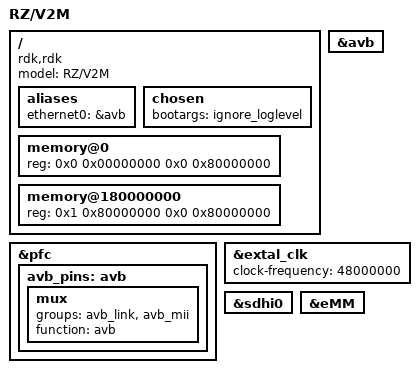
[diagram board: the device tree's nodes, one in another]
/* SPDX-License-Identifier: GPL-2.0 */
/*
 * Device Tree Source for the RZ/V2M RDK platform
 *
 * Copyright (C) 2020 Renesas Electronics Corp.
 */

/dts-v1/;
#include "r9a09g011gbg.dtsi"
#include <dt-bindings/gpio/gpio.h>

/ {
	model = "RZ/V2M";
	compatible = "rdk,rdk", "renesas,r9a09g011gbg";

	aliases {
		ethernet0 = &avb;
	};

	chosen {
		bootargs = "ignore_loglevel";
	};

	memory@0 {
		device_type = "memory";
		reg = <0x0 0x00000000 0x0 0x80000000>;
	};

	memory@180000000 {
                device_type = "memory";
                reg = <0x1 0x80000000 0x0 0x80000000>;
	};
};

&avb {
	status = "okay";
};

&pfc {
	avb_pins: avb {
		mux {
			groups = "avb_link", "avb_mii";
			function = "avb";
		};
	};
};

&extal_clk {
	clock-frequency = <48000000>;
};

&sdhi0 {
	status = "okay";
};

&eMM {
	status = "okay";
};
